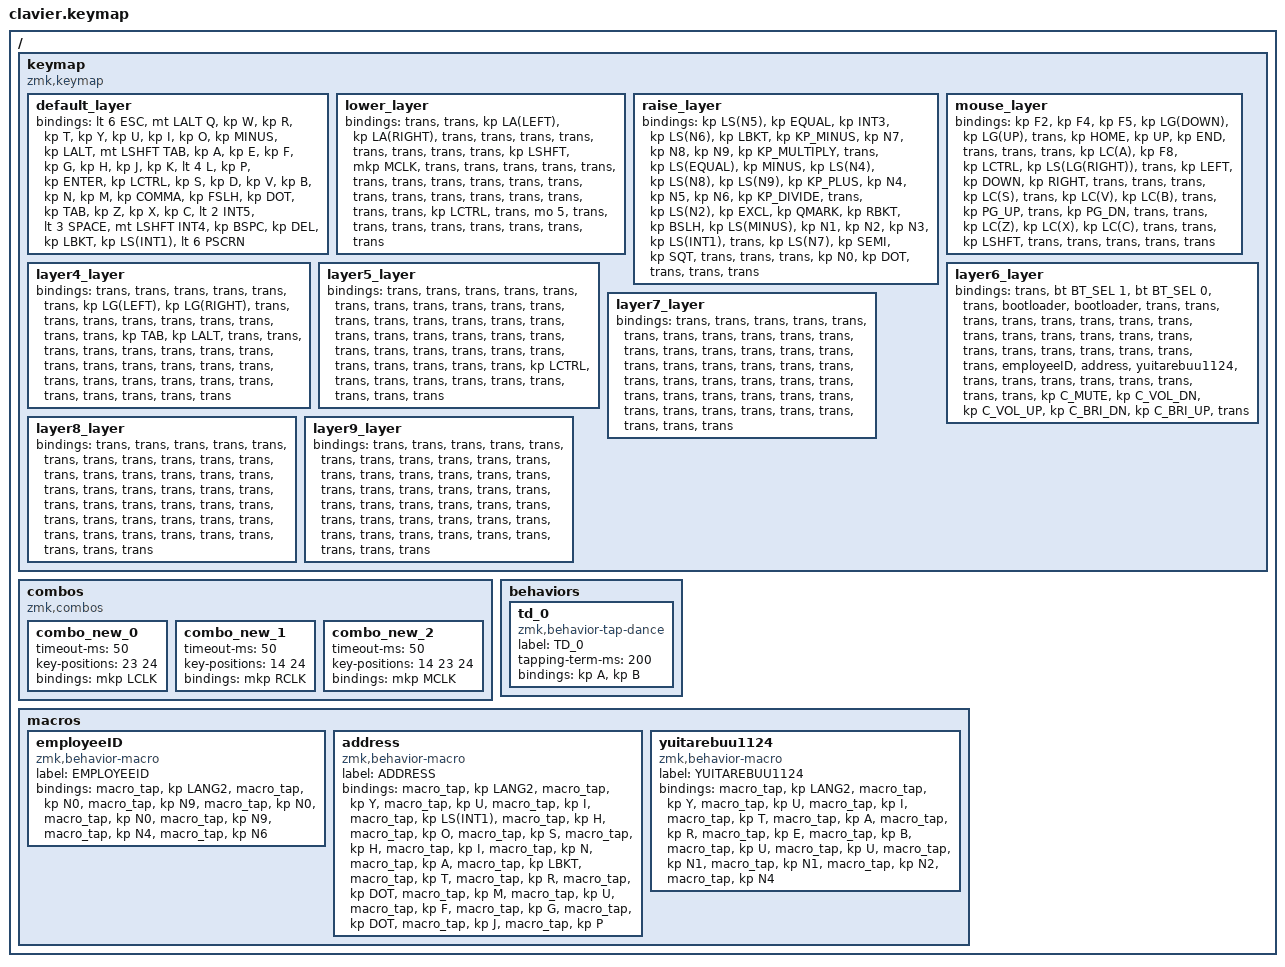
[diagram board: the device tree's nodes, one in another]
/*
 * ZMK Keymap - Generated by ZMK Keymap Editor
 * Do not edit manually unless you know what you're doing.
 */

#include <behaviors.dtsi>
#include <dt-bindings/zmk/bt.h>
#include <dt-bindings/zmk/keys.h>
#include <dt-bindings/zmk/outputs.h>
#include <dt-bindings/zmk/mouse.h>

#define DEFAULT 0
#define AUTOMOUSE 1
#define LAYER2 2
#define LAYER3 3
#define LAYER4 4
#define SCROLL 5
#define LAYER_6 6
#define LAYER_7 7
#define LAYER_8 8
#define LAYER_9 9

/ {
    keymap {
        compatible = "zmk,keymap";

        default_layer {
            bindings = <
                &lt 6 ESC  &mt LALT Q  &kp W  &kp R  &kp T  &kp Y  &kp U  &kp I  &kp O  &kp MINUS  &kp LALT  &mt LSHFT TAB  &kp A  &kp E  &kp F  &kp G  &kp H  &kp J  &kp K  &lt 4 L  &kp P  &kp ENTER  &kp LCTRL  &kp S  &kp D  &kp V  &kp B  &kp N  &kp M  &kp COMMA  &kp FSLH  &kp DOT  &kp TAB  &kp Z  &kp X  &kp C  &lt 2 INT5  &lt 3 SPACE  &mt LSHFT INT4  &kp BSPC  &kp DEL  &kp LBKT  &kp LS(INT1)  &lt 6 PSCRN
            >;
        };

        lower_layer {
            bindings = <
                &trans  &trans  &kp LA(LEFT)  &kp LA(RIGHT)  &trans  &trans  &trans  &trans  &trans  &trans  &trans  &trans  &kp LSHFT  &mkp MCLK  &trans  &trans  &trans  &trans  &trans  &trans  &trans  &trans  &trans  &trans  &trans  &trans  &trans  &trans  &trans  &trans  &trans  &trans  &trans  &kp LCTRL  &trans  &mo 5  &trans  &trans  &trans  &trans  &trans  &trans  &trans  &trans
            >;
        };

        raise_layer {
            bindings = <
                &kp LS(N5)  &kp EQUAL  &kp INT3  &kp LS(N6)  &kp LBKT  &kp KP_MINUS  &kp N7  &kp N8  &kp N9  &kp KP_MULTIPLY  &trans  &kp LS(EQUAL)  &kp MINUS  &kp LS(N4)  &kp LS(N8)  &kp LS(N9)  &kp KP_PLUS  &kp N4  &kp N5  &kp N6  &kp KP_DIVIDE  &trans  &kp LS(N2)  &kp EXCL  &kp QMARK  &kp RBKT  &kp BSLH  &kp LS(MINUS)  &kp N1  &kp N2  &kp N3  &kp LS(INT1)  &trans  &kp LS(N7)  &kp SEMI  &kp SQT  &trans  &trans  &trans  &kp N0  &kp DOT  &trans  &trans  &trans
            >;
        };

        mouse_layer {
            bindings = <
                &kp F2  &kp F4  &kp F5  &kp LG(DOWN)  &kp LG(UP)  &trans  &kp HOME  &kp UP  &kp END  &trans  &trans  &trans  &kp LC(A)  &kp F8  &kp LCTRL  &kp LS(LG(RIGHT))  &trans  &kp LEFT  &kp DOWN  &kp RIGHT  &trans  &trans  &trans  &kp LC(S)  &trans  &kp LC(V)  &kp LC(B)  &trans  &kp PG_UP  &trans  &kp PG_DN  &trans  &trans  &kp LC(Z)  &kp LC(X)  &kp LC(C)  &trans  &trans  &kp LSHFT  &trans  &trans  &trans  &trans  &trans
            >;
        };

        layer4_layer {
            bindings = <
                &trans  &trans  &trans  &trans  &trans  &trans  &kp LG(LEFT)  &kp LG(RIGHT)  &trans  &trans  &trans  &trans  &trans  &trans  &trans  &trans  &trans  &kp TAB  &kp LALT  &trans  &trans  &trans  &trans  &trans  &trans  &trans  &trans  &trans  &trans  &trans  &trans  &trans  &trans  &trans  &trans  &trans  &trans  &trans  &trans  &trans  &trans  &trans  &trans  &trans
            >;
        };

        layer5_layer {
            bindings = <
                &trans  &trans  &trans  &trans  &trans  &trans  &trans  &trans  &trans  &trans  &trans  &trans  &trans  &trans  &trans  &trans  &trans  &trans  &trans  &trans  &trans  &trans  &trans  &trans  &trans  &trans  &trans  &trans  &trans  &trans  &trans  &trans  &trans  &trans  &kp LCTRL  &trans  &trans  &trans  &trans  &trans  &trans  &trans  &trans  &trans
            >;
        };

        layer6_layer {
            bindings = <
                &trans  &bt BT_SEL 1  &bt BT_SEL 0  &trans  &bootloader  &bootloader  &trans  &trans  &trans  &trans  &trans  &trans  &trans  &trans  &trans  &trans  &trans  &trans  &trans  &trans  &trans  &trans  &trans  &trans  &trans  &trans  &trans  &employeeID  &address  &yuitarebuu1124  &trans  &trans  &trans  &trans  &trans  &trans  &trans  &trans  &kp C_MUTE  &kp C_VOL_DN  &kp C_VOL_UP  &kp C_BRI_DN  &kp C_BRI_UP  &trans
            >;
        };

        layer7_layer {
            bindings = <
                &trans  &trans  &trans  &trans  &trans  &trans  &trans  &trans  &trans  &trans  &trans  &trans  &trans  &trans  &trans  &trans  &trans  &trans  &trans  &trans  &trans  &trans  &trans  &trans  &trans  &trans  &trans  &trans  &trans  &trans  &trans  &trans  &trans  &trans  &trans  &trans  &trans  &trans  &trans  &trans  &trans  &trans  &trans  &trans
            >;
        };

        layer8_layer {
            bindings = <
                &trans  &trans  &trans  &trans  &trans  &trans  &trans  &trans  &trans  &trans  &trans  &trans  &trans  &trans  &trans  &trans  &trans  &trans  &trans  &trans  &trans  &trans  &trans  &trans  &trans  &trans  &trans  &trans  &trans  &trans  &trans  &trans  &trans  &trans  &trans  &trans  &trans  &trans  &trans  &trans  &trans  &trans  &trans  &trans
            >;
        };

        layer9_layer {
            bindings = <
                &trans  &trans  &trans  &trans  &trans  &trans  &trans  &trans  &trans  &trans  &trans  &trans  &trans  &trans  &trans  &trans  &trans  &trans  &trans  &trans  &trans  &trans  &trans  &trans  &trans  &trans  &trans  &trans  &trans  &trans  &trans  &trans  &trans  &trans  &trans  &trans  &trans  &trans  &trans  &trans  &trans  &trans  &trans  &trans
            >;
        };
    };

    combos {
        compatible = "zmk,combos";
        combo_new_0 {
            timeout-ms = <50>;
            key-positions = <23 24>;
            bindings = <&mkp LCLK>;
        };
        combo_new_1 {
            timeout-ms = <50>;
            key-positions = <14 24>;
            bindings = <&mkp RCLK>;
        };
        combo_new_2 {
            timeout-ms = <50>;
            key-positions = <14 23 24>;
            bindings = <&mkp MCLK>;
        };
    };
    behaviors {
        td_0: td_0 {
            compatible = "zmk,behavior-tap-dance";
            label = "TD_0";
            #binding-cells = <0>;
            tapping-term-ms = <200>;
            bindings = <&kp A>, <&kp B>;
        };
    };
    macros {
        employeeID: employeeID {
            compatible = "zmk,behavior-macro";
            label = "EMPLOYEEID";
            #binding-cells = <0>;
            bindings = <
                &macro_tap &kp LANG2
                &macro_tap &kp N0
                &macro_tap &kp N9
                &macro_tap &kp N0
                &macro_tap &kp N0
                &macro_tap &kp N9
                &macro_tap &kp N4
                &macro_tap &kp N6
            >;
        };
        address: address {
            compatible = "zmk,behavior-macro";
            label = "ADDRESS";
            #binding-cells = <0>;
            bindings = <
                &macro_tap &kp LANG2
                &macro_tap &kp Y
                &macro_tap &kp U
                &macro_tap &kp I
                &macro_tap &kp LS(INT1)
                &macro_tap &kp H
                &macro_tap &kp O
                &macro_tap &kp S
                &macro_tap &kp H
                &macro_tap &kp I
                &macro_tap &kp N
                &macro_tap &kp A
                &macro_tap &kp LBKT
                &macro_tap &kp T
                &macro_tap &kp R
                &macro_tap &kp DOT
                &macro_tap &kp M
                &macro_tap &kp U
                &macro_tap &kp F
                &macro_tap &kp G
                &macro_tap &kp DOT
                &macro_tap &kp J
                &macro_tap &kp P
            >;
        };
        yuitarebuu1124: yuitarebuu1124 {
            compatible = "zmk,behavior-macro";
            label = "YUITAREBUU1124";
            #binding-cells = <0>;
            bindings = <
                &macro_tap &kp LANG2
                &macro_tap &kp Y
                &macro_tap &kp U
                &macro_tap &kp I
                &macro_tap &kp T
                &macro_tap &kp A
                &macro_tap &kp R
                &macro_tap &kp E
                &macro_tap &kp B
                &macro_tap &kp U
                &macro_tap &kp U
                &macro_tap &kp N1
                &macro_tap &kp N1
                &macro_tap &kp N2
                &macro_tap &kp N4
            >;
        };
    };
};
